# YTM32B1HA0 register map
Vendor: YTMicro; File version: 1.0
CPU: little endian, MPU, FPU, 2 interrupt priority bits
Registers are 32-bit, read-write, reset 0x0 unless marked. A register's access mark holds for its fields unless they carry their own. Offsets are from the block's base; [hi:lo] are bit positions; {n}, {i} and the like mark numbered series; 'fields as' and 'values as' point back to an identical list.

## CIM — Chip Integration Module
Base 0x401EC000; register names take the prefix CIM_
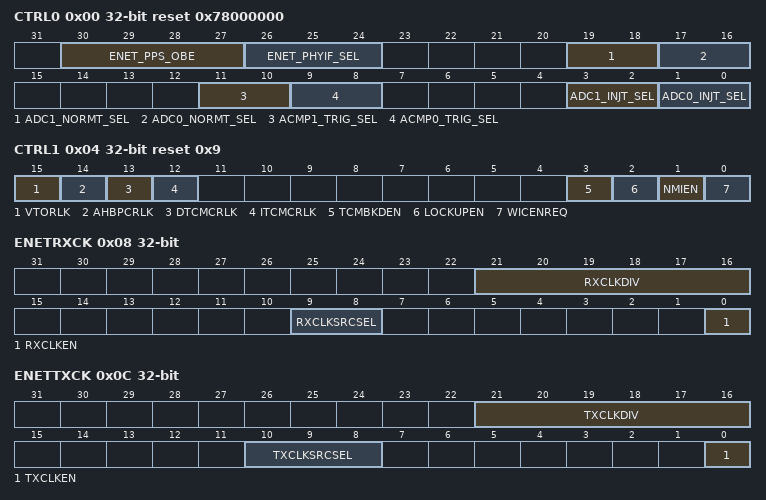
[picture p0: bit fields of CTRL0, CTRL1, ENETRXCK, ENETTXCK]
0x00 CTRL0 reset 0x78000000
  [30:27] ENET_PPS_OBE — Enable ENET Pulse Per Second Output, this field has 4 bits to control 4 channel output
    0=Pulse Per Second output disabled; 1=Pulse Per Second output enabled
  [26:24] ENET_PHYIF_SEL — Select ENET PHY interface
    0=MII; 4=RMII; 6=SMII; 7=RevMII
  [19:18] ADC1_NORMT_SEL — Select trigger source for ADC1 normal mode.
    0=PTU1 output; 1=TMU output synced by bus clock; 2=TMU output synced by ADC1 func clock
  [17:16] ADC0_NORMT_SEL — Select trigger source for ADC0 Normal mode.
    0=PTU0 output; 1=TMU output synced by bus clock; 2=TMU output synced by ADC0 func clock
  [11:10] ACMP1_TRIG_SEL — ACMP1 Trigger Select
    0=TMU; 1=TMU synced by bus clock; 2=TMU synced by ACMP1 func clock
  [9:8] ACMP0_TRIG_SEL — ACMP0 Trigger Select
    0=TMU; 1=TMU synced by bus clock; 2=TMU synced by ACMP0 func clock
  [3:2] ADC1_INJT_SEL — Select trigger source for ADC1 injection mode.
    1=TMU output synced by bus clock; 2=TMU output synced by ADC1 func clock
  [1:0] ADC0_INJT_SEL — Select trigger source for ADC0 injection mode.
    1=TMU output synced by bus clock; 2=TMU output synced by ADC0 func clock
0x04 CTRL1 reset 0x9
  [15] VTORLK — Lock CM7 VTOR Write
    0=VTOR Write not Locked; 1=VTOR Write Locked
  [14] AHBPCRLK — Lock AHBPCR Write
    0=AHBPCR Write not Locked; 1=AHBPCR Write Locked
  [13] DTCMCRLK — Lock DTCMCR Write
    0=DTCMCR Write not Locked; 1=DTCMCR Write Locked
  [12] ITCMCRLK — Lock ITCMCR Write
    0=ITCMCR Write not Locked; 1=ITCMCR Write Locked
  [3] TCMBKDEN — Enable TCM Backdoor Access through CM7 AHBS bus
    0=TCM Backdoor Access is disabled; 1=TCM Backdoor Access is enabled
  [2] LOCKUPEN — Enable CPU Lockup Reset
    0=CPU Lockup reset is disabled; 1=CPU Lockup reset is enabled
  [1] NMIEN — Enable NMI function
    0=NMI is disabled; 1=NMI is enabled
  [0] WICENREQ — Enable WIC to wakeup low power mode.
    0=Disable WIC to wakeup low power mode; 1=Enable WIC to wakeup low power mode
0x08 ENETRXCK
  [21:16] RXCLKDIV — Configure ENET Rx clock divider, divided by (RXCLK_DIV + 1)
  [9:8] RXCLKSRCSEL — Select ENET Rx clock source
    0=ENET_MII_RX_CLK from pad; 1=ENET_MII_RMII_TX_CLK from pad; 2=FIRC_CLK divided by 2; 3=FXOSC_CLK
  [0] RXCLKEN — Enable ENET Rx Clock
    0=ENET Rx Clock is disabled; 1=ENET Rx Clock is enabled
0x0C ENETTXCK
  [21:16] TXCLKDIV — Configure ENET Tx clock divider, divided by (TXCLK_DIV + 1)
  [10:8] TXCLKSRCSEL — Select ENET Tx clock source
    0=ENET_MII_RMII_TX_CLK from pad; 1=ENET_MII_RX_CLK from pad; 2=FIRC_CLK divided by 2; 3=FXOSC_CLK
  [0] TXCLKEN — Enable ENET Tx Clock
    0=ENET Tx Clock is disabled; 1=ENET Tx Clock is enabled
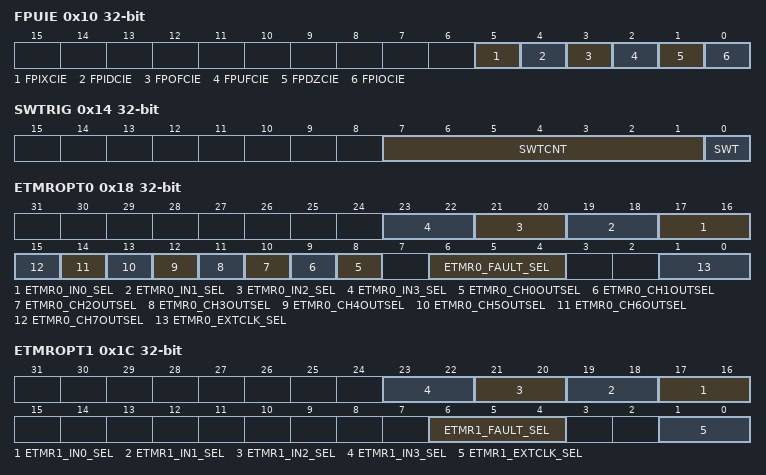
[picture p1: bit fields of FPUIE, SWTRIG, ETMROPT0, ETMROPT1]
0x10 FPUIE
  [all] fields
    0=Disable interrupt; 1=Enable interrupt
  [5] FPIXCIE
  [4] FPIDCIE
  [3] FPOFCIE
  [2] FPUFCIE
  [1] FPDZCIE
  [0] FPIOCIE
0x14 SWTRIG
  [7:1] SWTCNT — Define software trigger valid length (multiplied with bus clock cycle), SWTCNT value will decrease until equal to zero when SWT set.
  [0] SWT — Generate software trigger.
    0=Software trigger is disabled; 1=Generate software trigger and it keeps until SWTCNT equals to zero
0x18 ETMROPT0
  [2n+17:2n+16] ETMR0_IN{n}_SEL (n=0..3) — Select eTMR0 channel{n} input sources.
    0=Select ETMR0_CH{n} input from pad; 1=Select TMU output; 2=Hall sensor XOR input (XOR of ETMR0_CH0/1/2)
  [n+8] ETMR0_CH{n}OUTSEL (n=0..7) — Select modulation with eTMR1_CH1 for eTMR0 channel {n}.
    0=eTMR0 channel {n} output to pad directly; 1=eTMR0 channel {n} output modulation with eTMR1_CH1 output
  [6:4] ETMR0_FAULT_SEL — Select fault source for eTMR0.
    0=eTMR0 fault 0 input from pad; 1=eTMR0 fault 0 input from TMU; 0=eTMR0 fault 1 input from pad; 2=eTMR0 fault 1 input from TMU; 0=eTMR0 fault 2 input from pad; 4=eTMR0 fault 2 input from TMU
  [1:0] ETMR0_EXTCLK_SEL — Select external clock source for eTMR0.
    0=Select TCLK_IN0 input as external clock for eTMR0; 1=Select TCLK_IN1 input as external clock for eTMR0; 2=Select TCLK_IN2 input as external clock for eTMR0; 3=Select ETMR0_FUNC_CLK from IPC as external clock for eTMR0
0x1C ETMROPT1
  [2n+17:2n+16] ETMR1_IN{n}_SEL (n=0..3) — Select eTMR1 channel{n} input sources.
    0=Select ETMR1_CH{n} input from pad; 1=Select TMU output; 2=Hall sensor XOR input (XOR of ETMR1_CH0/1/2)
  [6:4] ETMR1_FAULT_SEL — Select fault source for eTMR1.
    0=eTMR1 fault 0 input from pad; 1=eTMR1 fault 0 input from TMU; 0=eTMR1 fault 1 input from pad; 2=eTMR1 fault 1 input from TMU; 0=eTMR1 fault 2 input from pad; 4=eTMR1 fault 2 input from TMU
  [1:0] ETMR1_EXTCLK_SEL — Select external clock source for eTMR1.
    0=Select TCLK_IN0 input as external clock for eTMR1; 1=Select TCLK_IN1 input as external clock for eTMR1; 2=Select TCLK_IN2 input as external clock for eTMR1; 3=Select ETMR1_FUNC_CLK from IPC as external clock for eTMR1
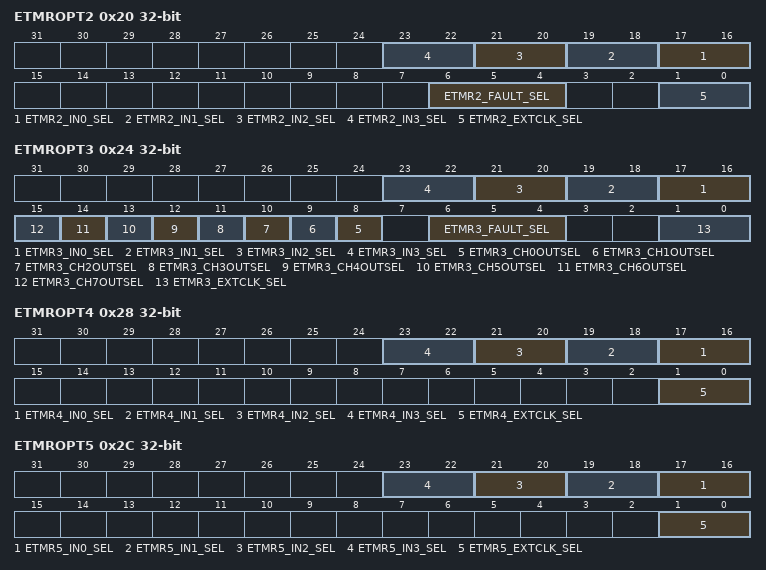
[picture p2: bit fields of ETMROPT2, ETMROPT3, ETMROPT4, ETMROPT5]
0x20 ETMROPT2
  [2n+17:2n+16] ETMR2_IN{n}_SEL (n=0..3) — Select eTMR2 channel{n} input sources.
    0=Select ETMR2_CH{n} input from pad; 1=Select TMU output; 2=Hall sensor XOR input 1 (XOR of ETMR2_CH0/1/2); 3=Hall sensor XOR input 2 (XOR of ETMR2_CH0,ETMR2_CH1,ETMR1_CH1)
  [6:4] ETMR2_FAULT_SEL — Select fault source for eTMR2.
    0=eTMR2 fault 0 input from pad; 1=eTMR2 fault 0 input from TMU; 0=eTMR2 fault 1 input from pad; 2=eTMR2 fault 1 input from TMU; 0=eTMR2 fault 2 input from pad; 4=eTMR2 fault 2 input from TMU
  [1:0] ETMR2_EXTCLK_SEL — Select external clock source for eTMR2.
    0=Select TCLK_IN0 input as external clock for eTMR2; 1=Select TCLK_IN1 input as external clock for eTMR2; 2=Select TCLK_IN2 input as external clock for eTMR2; 3=Select ETMR2_FUNC_CLK from IPC as external clock for eTMR2
0x24 ETMROPT3
  [2n+17:2n+16] ETMR3_IN{n}_SEL (n=0..3) — Select eTMR3 channel{n} input sources.
    0=Select ETMR3_CH{n} input from pad; 1=Select TMU output; 2=Hall sensor XOR input (XOR of ETMR3_CH0/1/2)
  [n+8] ETMR3_CH{n}OUTSEL (n=0..7) — Select modulation with eTMR2_CH1 for eTMR3 channel {n}.
    0=eTMR3 channel {n} output to pad directly; 1=eTMR3 channel {n} output modulation with eTMR2_CH1 output
  [6:4] ETMR3_FAULT_SEL — Select fault source for eTMR3.
    0=eTMR3 fault 0 input from pad; 1=eTMR3 fault 0 input from TMU; 0=eTMR3 fault 1 input from pad; 2=eTMR3 fault 1 input from TMU; 0=eTMR3 fault 2 input from pad; 4=eTMR3 fault 2 input from TMU
  [1:0] ETMR3_EXTCLK_SEL — Select external clock source for eTMR3.
    0=Select TCLK_IN0 input as external clock for eTMR3; 1=Select TCLK_IN1 input as external clock for eTMR3; 2=Select TCLK_IN2 input as external clock for eTMR3; 3=Select ETMR3_FUNC_CLK from IPC as external clock for eTMR3
0x28 ETMROPT4
  [2n+17:2n+16] ETMR4_IN{n}_SEL (n=0..3) — Select eTMR4 channel{n} input sources.
    0=Select ETMR4_CH{n} input from pad; 1=Select TMU output; 2=Hall sensor XOR input (XOR of ETMR4_CH0/1/2)
  [1:0] ETMR4_EXTCLK_SEL — Select external clock source for eTMR4.
    0=Select TCLK_IN0 input as external clock for eTMR4; 1=Select TCLK_IN1 input as external clock for eTMR4; 2=Select TCLK_IN2 input as external clock for eTMR4; 3=Select ETMR4_FUNC_CLK from IPC as external clock for eTMR4
0x2C ETMROPT5
  [2n+17:2n+16] ETMR5_IN{n}_SEL (n=0..3) — Select eTMR5 channel{n} input sources.
    0=Select ETMR5_CH{n} input from pad; 1=Select TMU output; 2=Hall sensor XOR input (XOR of ETMR5_CH0/1/2)
  [1:0] ETMR5_EXTCLK_SEL — Select external clock source for eTMR5.
    0=Select TCLK_IN0 input as external clock for eTMR5; 1=Select TCLK_IN1 input as external clock for eTMR5; 2=Select TCLK_IN2 input as external clock for eTMR5; 3=Select ETMR5_FUNC_CLK from IPC as external clock for eTMR5
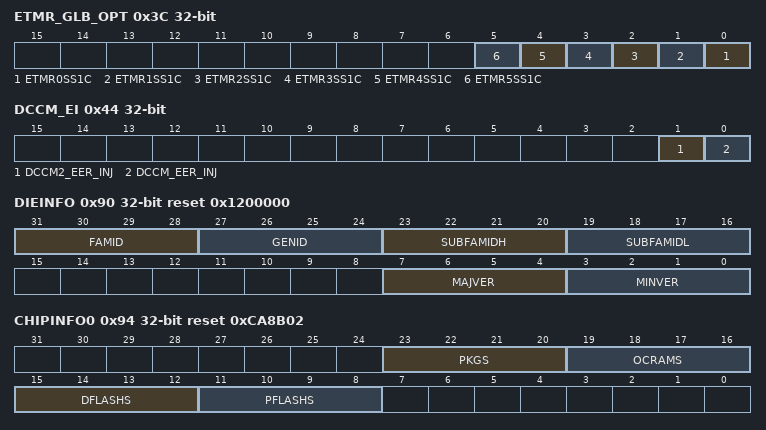
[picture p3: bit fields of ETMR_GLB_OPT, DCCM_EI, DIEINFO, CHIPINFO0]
0x3C ETMR_GLB_OPT
  [n] ETMR{n}SS1C (n=0..5) — Generate synchronize signal for eTMR{n} trigger 1.
    0=Don't generate synchronize signal for eTMR{n} trigger 1; 1=Generate synchronize signal for eTMR{n} trigger 1
0x40 SWFAULT
  [0] SW_FAULT — Writing 1 to this bit will generate a software fault to FMU.Writing 0 to clear.
    0=No software fault; 1=Software fault assert
0x44 DCCM_EI
  [1] DCCM2_EER_INJ — Writing 1 to this bit will generate a lockstep fault.
  [0] DCCM_EER_INJ — Writing 1 to this bit will generate a lockstep fault.
{0x80+4i} UID{i} ro (i=0..3)
  [31:0] UID{i} — Unique identification for the chip.
0x90 DIEINFO ro reset 0x1200000
  [31:28] FAMID — Describe the product family information.
    0=B - Basic(General); 1=D - Dashboard; 2=P - Powertrain; 3=V - Vision; 4=N - Networks
  [27:24] GENID — Describe the product generation information.
    1=1st generation production; 2=2nd generation production; 3=3rd generation production
  [23:20] SUBFAMIDH — Describe the product sub family information.
    0=L - Low end; 1=M - Middle end; 2=H - High end
  [19:16] SUBFAMIDL — Describe the product max Flash size information.
    0=A - 2M; 1=B - 4M; 2=C - 6M; 3=D - 8M; 4=E - 16MB
  [7:4] MAJVER — Describe the major version information.
  [3:0] MINVER — Describe the minor version information.
0x94 CHIPINFO0 ro reset 0xCA8B02
  [23:20] PKGS — Describe chip package type information.
    0=16 TSOP; 1=32 LQFP; 2=32 QFN; 3=48 LQFP; 4=64 LQFP; 8=100 LQFP; 10=144 LQFP; 12=176 LQFP; 13=257 BGA; 15=289 BGA
  [19:16] OCRAMS — Describe ocram size information.
    2=1KB; 3=2KB; 4=4KB; 5=8KB; 6=16KB; 7=32KB; 8=64KB; 9=128KB; 10=256KB; 11=512KB; 12=1MB; 13=2MB; 14=4MB; 15=8MB
  [15:12] DFLASHS — Describe data flash size information.
    0=1KB; 1=2KB; 2=4KB; 3=8KB; 4=16KB; 5=32KB; 6=64KB; 7=128KB; 8=256KB; 9=512KB
  [11:8] PFLASHS — Describe program flash size information.
    0=1KB; 1=2KB; 2=4KB; 3=8KB; 4=16KB; 5=32KB; 6=64KB; 7=128KB; 8=256KB; 9=512KB; 10=1MB; 11=2MB; 12=4MB; 13=8MB; 14=16MB; 15=32MB
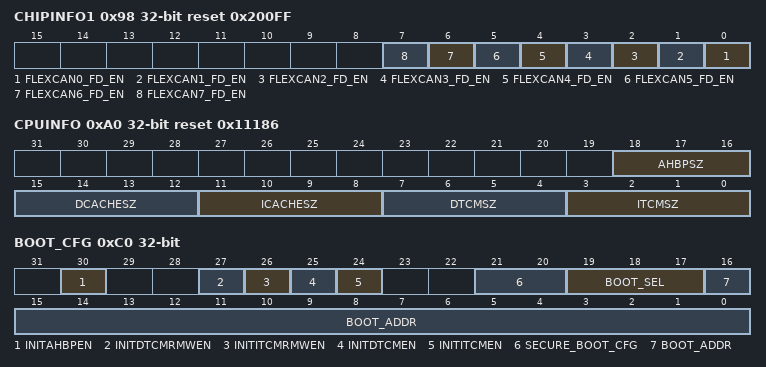
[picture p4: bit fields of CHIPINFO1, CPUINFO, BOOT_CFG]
0x98 CHIPINFO1 ro reset 0x200FF
  [n] FLEXCAN{n}_FD_EN (n=0..7) — FlexCAN{n} FD Feature Enable/Disable
    0=FlexCAN{n} FD Feature is disabled; 1=FlexCAN{n} FD Feature is enabled
0xA0 CPUINFO ro reset 0x11186
  [18:16] AHBPSZ — Describe AHBP size information.
    0=AHBP disabled; 1=64MB; 2=128MB; 3=256MB; 4=512MB
  [15:12] DCACHESZ — Describe Data Cache size information.
    0=4KB; 1=8KB; 3=16KB; 7=32KB; 15=64KB
  [11:8] ICACHESZ — Describe Instruction Cache size information
    0=4KB; 1=8KB; 3=16KB; 7=32KB; 15=64KB
  [7:4] DTCMSZ — Describe DTCM size information
    0=No TCM implemented; 3=4KB; 4=8KB; 5=16KB; 6=32KB; 7=64KB; 8=128KB; 9=256KB; 10=512KB; 11=1MB; 12=2MB; 13=4MB; 14=8MB; 15=16MB
  [3:0] ITCMSZ — Describe ITCM size information
    values as DTCMSZ
0xC0 BOOT_CFG
  [30] INITAHBPEN — Configure AHBP enable or disable out of reset
    0=AHBP disable out of reset; 1=AHBP enable out of reset
  [27] INITDTCMRMWEN — Configure DTCM read modify write enable or disable out of reset
    0=DTCM read modify write disable out of reset; 1=DTCM read modify write enable out of reset
  [26] INITITCMRMWEN — Configure ITCM read modify write enable or disable out of reset
    0=ITCM read modify write disable out of reset; 1=ITCM read modify write enable out of reset
  [25] INITDTCMEN — Configure DTCM enable or disable out of reset
    0=DTCM disable out of reset; 1=DTCM enable out of reset
  [24] INITITCMEN — Configure ITCM enable or disable out of reset
    0=ITCM disable out of reset; 1=ITCM enable out of reset
  [21:20] SECURE_BOOT_CFG ro — Configure secure boot from ROM
    0=Nonsecure boot; 1=Nonsecure boot; 2=Secure boot from ROM; 3=Nonsecure boot
  [19:17] BOOT_SEL — Select the base address chip boot from
    0=Flash base; 1=OCRAML base; 2=OCRAMU base; 3=ROM base; 4=ITCM base; 5=DFLASH base; 6=Address configured in BOOT_ADDR[31:15]; 7=QSPI base
  [16:0] BOOT_ADDR — BOOT_ADDR configures the address chip boot from, valid when BOO_SEL is 0b110. BOOT_ADDR is from the boot address's Bit31~Bit15, lower 15 bits are masked, which means the address chip boot from is 32KB aligned.
